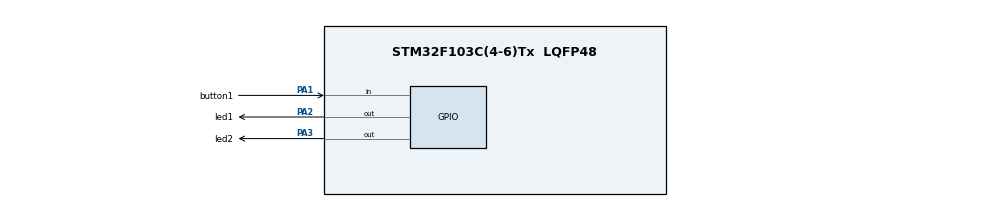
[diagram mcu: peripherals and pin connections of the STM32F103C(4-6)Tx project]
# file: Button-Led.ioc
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Mcu.Family=STM32F1
Mcu.Name=STM32F103C(4-6)Tx
Mcu.Package=LQFP48
NVIC.PriorityGroup=NVIC_PRIORITYGROUP_4
PA1.GPIO_Label=button1
PA1.GPIO_PuPd=GPIO_PULLUP
PA1.Signal=GPIO_Input
PA2.GPIO_Label=led1
PA2.Signal=GPIO_Output
PA3.GPIO_Label=led2
PA3.PinState=GPIO_PIN_SET
PA3.Signal=GPIO_Output
ProjectManager.HeapSize=0x200
ProjectManager.StackSize=0x400
ProjectManager.TargetToolchain=STM32CubeIDE
RCC.APB1Freq_Value=8000000
RCC.APB2Freq_Value=8000000
RCC.SYSCLKSource=RCC_SYSCLKSOURCE_PLLCLK
board=custom

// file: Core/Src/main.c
/* USER CODE BEGIN Header */
/**
  ******************************************************************************
  * @file           : main.c
  * @brief          : Main program body
  ******************************************************************************
  * @attention
  *
  * Copyright (c) 2023 STMicroelectronics.
  * All rights reserved.
  *
  * This software is licensed under terms that can be found in the LICENSE file
  * in the root directory of this software component.
  * If no LICENSE file comes with this software, it is provided AS-IS.
  *
  ******************************************************************************
  */
/* USER CODE END Header */
#include "main.h"

void SystemClock_Config(void);
static void MX_GPIO_Init(void);

int main(void)
{

  /* MCU Configuration--------------------------------------------------------*/

  /* Reset of all peripherals, Initializes the Flash interface and the Systick. */
  HAL_Init();

  /* Configure the system clock */
  SystemClock_Config();

  /* Initialize all configured peripherals */
  MX_GPIO_Init();

  /* Infinite loop */
  while (1)
  {

    /* USER CODE BEGIN 3 */
	 // HAL_GPIO_WritePin(led1_GPIO_Port, led1_Pin, GPIO_PIN_SET);
	  //HAL_GPIO_WritePin(led2_GPIO_Port, led2_Pin, GPIO_PIN_RESET);
	 if(HAL_GPIO_ReadPin(button1_GPIO_Port,button1_Pin)==0){
	  HAL_GPIO_TogglePin(GPIOA,led1_Pin);
	  //HAL_Delay(1000);
	  HAL_GPIO_TogglePin(GPIOA,led2_Pin);
	  //HAL_Delay(100);
	 }
  }
  /* USER CODE END 3 */
}

void SystemClock_Config(void)
{
  RCC_OscInitTypeDef RCC_OscInitStruct = {0};
  RCC_ClkInitTypeDef RCC_ClkInitStruct = {0};

  /** Initializes the RCC Oscillators according to the specified parameters
  * in the RCC_OscInitTypeDef structure.
  */
  RCC_OscInitStruct.OscillatorType = RCC_OSCILLATORTYPE_HSI;
  RCC_OscInitStruct.HSIState = RCC_HSI_ON;
  RCC_OscInitStruct.HSICalibrationValue = RCC_HSICALIBRATION_DEFAULT;
  RCC_OscInitStruct.PLL.PLLState = RCC_PLL_ON;
  RCC_OscInitStruct.PLL.PLLSource = RCC_PLLSOURCE_HSI_DIV2;
  RCC_OscInitStruct.PLL.PLLMUL = RCC_PLL_MUL2;
  if (HAL_RCC_OscConfig(&RCC_OscInitStruct) != HAL_OK)
  {
    Error_Handler();
  }

  /** Initializes the CPU, AHB and APB buses clocks
  */
  RCC_ClkInitStruct.ClockType = RCC_CLOCKTYPE_HCLK|RCC_CLOCKTYPE_SYSCLK
                              |RCC_CLOCKTYPE_PCLK1|RCC_CLOCKTYPE_PCLK2;
  RCC_ClkInitStruct.SYSCLKSource = RCC_SYSCLKSOURCE_PLLCLK;
  RCC_ClkInitStruct.AHBCLKDivider = RCC_SYSCLK_DIV1;
  RCC_ClkInitStruct.APB1CLKDivider = RCC_HCLK_DIV1;
  RCC_ClkInitStruct.APB2CLKDivider = RCC_HCLK_DIV1;

  if (HAL_RCC_ClockConfig(&RCC_ClkInitStruct, FLASH_LATENCY_0) != HAL_OK)
  {
    Error_Handler();
  }
}

static void MX_GPIO_Init(void)
{
  GPIO_InitTypeDef GPIO_InitStruct = {0};

  /* GPIO Ports Clock Enable */
  __HAL_RCC_GPIOA_CLK_ENABLE();

  /*Configure GPIO pin Output Level */
  HAL_GPIO_WritePin(led1_GPIO_Port, led1_Pin, GPIO_PIN_RESET);

  /*Configure GPIO pin Output Level */
  HAL_GPIO_WritePin(led2_GPIO_Port, led2_Pin, GPIO_PIN_SET);

  /*Configure GPIO pin : button1_Pin */
  GPIO_InitStruct.Pin = button1_Pin;
  GPIO_InitStruct.Mode = GPIO_MODE_INPUT;
  GPIO_InitStruct.Pull = GPIO_PULLUP;
  HAL_GPIO_Init(button1_GPIO_Port, &GPIO_InitStruct);

  /*Configure GPIO pins : led1_Pin led2_Pin */
  GPIO_InitStruct.Pin = led1_Pin|led2_Pin;
  GPIO_InitStruct.Mode = GPIO_MODE_OUTPUT_PP;
  GPIO_InitStruct.Pull = GPIO_NOPULL;
  GPIO_InitStruct.Speed = GPIO_SPEED_FREQ_LOW;
  HAL_GPIO_Init(GPIOA, &GPIO_InitStruct);

}

void Error_Handler(void)
{
  __disable_irq();
  while (1)
  {
  }
}
